# LIN_LIN_52400000h register map
Vendor: Texas Instruments
Registers are 32-bit, read-write, reset 0x0 unless marked. A register's access mark holds for its fields unless they carry their own. Offsets are as the file gives them; [hi:lo] are bit positions; <NAME> marks a mode.

## LIN (part 2 of 2)
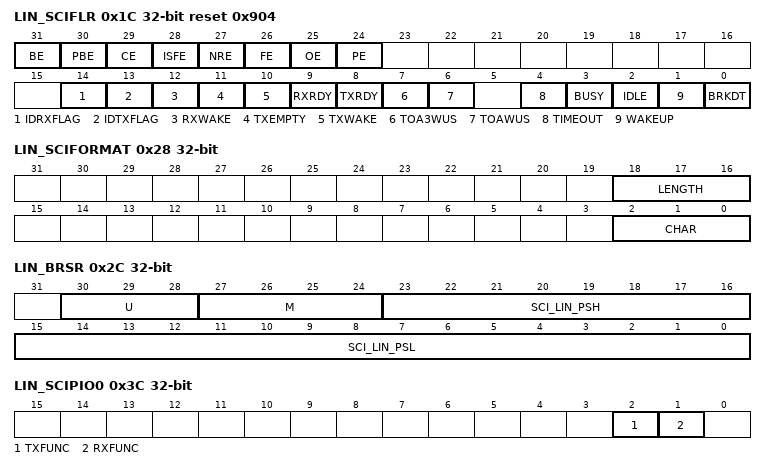
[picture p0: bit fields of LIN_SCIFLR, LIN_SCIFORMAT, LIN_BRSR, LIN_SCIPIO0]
0x1C LIN_SCIFLR access not given reset 0x904 — The SCIFLR register indicates the current status of the various interrupt sources of the LIN module.
  [31] BE — Bit Error Flag.This bit is effective in LIN mode only. This bit is set when there has been a bit error. This is detected by the bit monitor in the internal bit monitor. This bit is cleared by:- Reading the corresponding interrupt offset in the SCIINTVECT0/1 register- Setting the SWnRESET bit [SCIGCR1.7]- RESET bit [SCIGCR0.0]- System reset- Writing a 1 to this bit- Reception of a new sync break This field is writable in LIN mode only. 0 No bit error detected.1 Bit error detected. (access R/W1TC)
  [30] PBE — Physical Bus Error Flag.This bit is effective in LIN mode only. This bit is set when there has been a physical bus error. This is detected by the bit monitor in TED. This bit is cleared by:- Reading the corresponding interrupt offset in the SCIINTVECT0/1 register- Setting the SWnRESET bit [SCIGCR1.7]- RESET bit [SCIGCR0.0]- System reset- Writing a 1 to this bit- Reception of a new sync break Note: thie PBE will ony be flagged if no sync break can be generated. [because of a bus shortage to VBAT] or if no sync break delimeter can be generated [because of a bus shortage to GND]. This field is writable in LIN mode only. 0 No physiscal bus error detected.1 Physical bus error detected. (access R/W1TC)
  [29] CE — Checksum Error Flag. This bit is effective in LIN mode only. This bit is set when there is checksum error detected by a receiving node. The type of checksum to be used depends on the SCIGCR1.CTYPE bit. This bit is cleared by:- Reading the corresponding interrupt offset in the SCIINTVECT0/1 register- Setting the SWnRESET bit [SCIGCR1.7]- RESET bit [SCIGCR0.0]- System reset- Writing a 1 to this bit- Reception of a new sync break This field is writable in LIN mode only. 0 No Checksum error detected.1 Checksum error detected. (access R/W1TC)
  [28] ISFE — Inconsistent Sync Field Error Flag.This bit is effective in LIN mode only. This bit is set when there has been an inconsistent Sync Field error detected by the synchronizer during header reception. See the 'Header Reception and Adaptive Baudrate' section for more information. This bit is cleared by:- Reading the corresponding interrupt offset in the SCIINTVECT0/1 register- Setting the SWnRESET bit [SCIGCR1.7]- RESET bit [SCIGCR0.0]- System reset- Writing a 1 to this bit- Reception of a new sync break This field is writable in LIN mode only. 0 No Inconsistent Sync Field error detected.1 Inconsistent Sync Field error detected. (access R/W1TC)
  [27] NRE — No-Response Error Flag.This bit is effective in LIN mode only. This bit is set when there is no response to a master's header completed within TFRAME_MAX. This timeout period is applied for message frames of unknown length [identifiers 0 to 61]. This error is detected by the synchronizer of the module. This bit is cleared by:- Reading the corresponding interrupt offset in the SCIINTVECT0/1 register- Setting the SWnRESET bit [SCIGCR1.7]- RESET bit [SCIGCR0.0]- System reset- Writing a 1 to this bit- Reception of a new sync break This field is writable in LIN mode only. 0 No No-Response error detected.1 No-Response error detected. (access R/W1TC)
  [26] FE — Framing error flag.This bit is effective in LIN or SCI-compatible mode. This bit is set when an expected stop bit is not found. In SCI compatible mode, only the first stop bit is checked. The missing stop bit indicates that synchronization with the start bit has been lost and that the character is incorrectly framed. Detection of a framing error causes the SCI to generate an error interrupt if the RXERR INT ENA bit is set. This bit is cleared by:- Reading the corresponding interrupt offset in the SCIINTVECT0/1 register- Setting the SWnRESET bit [SCIGCR1.7]- RESET bit [SCIGCR0.0]- System reset- Writing a 1 to this bit- Reception of a new character [SCI-compatible mode], or frame [LIN mode]In multibuffer mode the frame is defined in the SCIFORMAT register. 0 No framing error detected.1 Framing error detected. (access R/W1TC)
  [25] OE — Overrun error flag.This bit is effective in LIN or SCI-compatible mode. This bit is set when the transfer of data from SCIRXSHF to SCIRD overwrites unread data already in SCIRD or the RDy buffers. Detection of an overrun error causes the LIN to generate an error interrupt if the SET OE INT bit is one. This bit is cleared by:- Reading the corresponding interrupt offset in the SCIINTVECT0/1 register- Setting the SWnRESET bit [SCIGCR1.7]- RESET bit [SCIGCR0.0]- System reset- Writing a 1 to this bit 0 No overrun error detected.1 Overrun error detected. (access R/W1TC)
  [24] PE — Parity error flag.This bit is effective in LIN or SCI-compatible mode. This bit is set when a parity error is detected in the received data. In SCI address-bit mode, the parity is calculated on the data and address bit fields of the received frame. In idle-line mode, only the data is used to calculate parity. An error is generated when a character is received with a mismatch between the number of 1s and its parity bit. For more information on parity checking, see the 'SCI Global Control Register [SCIGCR1]' description. If the parity function is disabled [that is, SCIGCR1.2 = 0], the PE flag is disabled and read as 0. Detection of a parity error causes the LIN to generate an error interrupt if the SET PE INT bit = 1. This bit is cleared by:- Reading the corresponding interrupt offset in the SCIINTVECT0/1 register- Setting the SWnRESET bit [SCIGCR1.7]- RESET bit [SCIGCR0.0]- System reset- Reception of a new charcter [SCI-compatible mode] or frame [LIN mode]- Writing a 1 to this bit 0 No parity error or parity disabled.1 Parity error detected. (access R/W1TC)
  [14] IDRXFLAG — Identifier On Receive Flag.This bit is effective in LIN mode only. This flag is set once an identifier is received with an RX match and no ID-parity error. See the 'Message Filtering and Validation' section for more details. When this flag is set it indicates that a new valid identifier has been received on an RX match. This bit is cleared by:- Reading the corresponding interrupt offset in the SCIINTVECT0/1 register- Setting the SWnRESET bit [SCIGCR1.7]- RESET bit [SCIGCR0.0]- System reset- Reading the LINID register- Writing a 1 to this bit This field is writable in LIN mode only. 0 No valid ID received.1 Valid ID RX received in LINID[23:16] on RX match. (access R/W1TC)
  [13] IDTXFLAG — Identifier On Transmit Flag.This bit is effective in LIN mode only. This flag is set once an identifier is received with a TX match and no ID-parity error. See the 'Message Filtering and Validation' section for more details. When this flag is set it indicates that a new valid identifier has been received on a TX match. This bit is cleared by: - Reading the corresponding interrupt offset in the SCIINTVECT0/1 register- RESET bit [SCIGCR0.0]- Setting SWnRESET- System reset- Reading the LINID register- Writing a 1 to this bit This field is writable in LIN mode only. 0 No valid ID received.1 Valid ID received in LINID[23:16] on TX match. (access R/W1TC)
  [12] RXWAKE ro — Receiver wakeup detect flag.This bit is effective in SCI-compatible mode only. The SCI sets this bit to indicate that the data currently in SCIRD is an address. This bit is cleared by:- RESET bit- Setting the SWnRESET bit [SCIGCR1.7]- System reset- Receipt of a data frame This bit is writable in SCI mode only. 0 The data in SCIRD is not an address.1 The data in SCIRD is an address.See [1] Section 3.4.4, Sleep Mode for Multiprocessor Communication, on page 16 for more information on using the RXWAKE bit with sleep mode.
  [11] TXEMPTY ro — Transmitter Empty flag.The value of this flag indicates the contents of the transmitter's buffer register[s] [SCITD/TDy] and shift register [SCITXSHF]. In multibuffer mode, this flag indicates the value of the TDx registers and shift register [SCITXSHF]. In non multibuffer mode, this flag indicates the value of LINTD0 [byte] and shift register [SCITXSHF]. This bit is set by: - RESET bit [SCIGCR0.0]- Setting the SWnRESET bit [SCIGCR1.7]- System reset. Note: This bit does not cause an interrupt request. 0 Compatible mode or LIN with no multibuffer:Transmitter buffer or shift register (or both) are loaded with data.In LIN mode using multibuffer mode:Multibuffer or shift register (or all) are loaded with data.1 Compatible mode or LIN with no multibuffer:Transmitter buffer and shift registers are both empty.In LIN mode using multibuffer mode:Multibuffer and shift registers are all empty.
  [10] TXWAKE rw — SCI transmitter wakeup method select.This bit is effective in SCI-compatible mode only. The TXWAKE bit controls whether the data in SCITD should be sent as an address or data frame using multiprocessor communication format. This bit is set to 1 or 0 by software before a byte is written to SCITD and is cleared by the SCI when data is transferred from SCITD to SCITXSHF or by a system reset. TXWAKE is not cleared by the SWnRESET bit [SCIGCR1.7]. 0 Address-bit mode: Frame to be transmitted will be data (address bit = 0).Idle- line mode: Frame to be transmitted will be data.1 Address-bit mode:Frame to be transmitted will be an address (address bit=1).Idle-line mode:Following frame to be transmitted will be an address (writing a 1 to this bit followed by writing dummy data to the SCITD will result in a idle period of 11 bit periods before the next frame is transmitted).
  [9] RXRDY — Receiver ready flag. In SCI compatibility mode, the receiver sets this bit to indicate that the SCIRD contains new data and is ready to be read by the CPU. In LIN mode, RXRDY is set once a valid frame is received in multibuffer mode, a valid frame being a message frame received with no errors. In non multibuffer mode RXRDY is set for each received byte and will be set for the last byte of the frame if there are no errors. The SCI/LIN generates a receive interrupt when RXRDY flag bit is setif the interrupt-enable bit is set [SCISETINT.9]. RXRDY is cleared by:- RESET bit [SCIGCR0.0]- Setting the SWnRESET- System reset- Writing a 1 to this bit- Reading SCIRD in while in SCI compatibility mode- Reading last data byte RDy of the response in LIN mode Note: The RXRDY flag cannot be cleared by Reading the corresponding interrupt offset in the SCIINTVECT0/1 register. 0 No new data in SCIRD/RDy.1 New data ready to be read from SCIRD. (access R/W1TC)
  [8] TXRDY ro — Transmitter buffer register ready flag.When set, this bit indicates that the transmit buffer[s] register [SCITD in compatibility mode and LINTD0, LINTD1 in MBUF mode] is/are ready to get another character from a CPU write. In SCI compatibility mode, Writing data to SCITD automatically clears this bit. In LIN mode, this bit is cleared once byte 0 [TD0] is written to LINTD0. This bit is set after the data of the TX buffer are shifted into the SCITXSHF register. This event can trigger a transmit DMA event if the DMA enable bit is set. This bit is set to 1 by:- RESET bit [SCIGCR0.0]- Setting the SWnRESET [SCIGCR1.7]- System reset Note: The TXRDY flag cannot be cleared by Reading the corresponding interrupt offset in the SCIINTVECT0/1 register. Note: The transmit interrupt request can be eliminated until the next series of data is written into the transmit buffers LINTD0 and LINTD1, by disaLINg the corresponding interrupt via the SCICLEARINT register or by disaLINg the transmitter via the TXENA bit [SCIGCR1.25=0]. 0 Compatible mode: SCITD is full.LIN mode: The multibuffers are full.1 Compatible mode: SCITD is ready to receive the next character.LIN mode: The multibuffers are ready to receive the next character(s).
  [7] TOA3WUS — Timeout After 3 Wakeup Signals flag.This bit is effective in LIN mode only. This flag is set if there is no Sync Break received after 3 wakeup signals and a period of 1.5 seconds have passed. Such expiration time is used before issuing another round of wakeup signals. This bit is cleared by:- Reading the corresponding interrupt offset in the SCIINTVECT0/1 register- Setting the SWnRESET bit [SCIGCR1.7]- RESET bit [SCIGCR0.0]- System reset- Writing a 1 to this bit This field is writable in LIN mode only. 0 No timeout after 3 wakeup signals.1 Timeout after 3 wakeup signals and 1.5s time. (access R/W1TC)
  [6] TOAWUS — Timeout After Wakeup Signal flag.This bit is effective in LIN mode only. This bit is set if there is no Sync Break received after a wakeup signal has been sent. A minimum of 150 ms expiration time is used before issuing another wakeup signal. This bit is cleared by:- Reading the corresponding interrupt offset in the SCIINTVECT0/1 register- Setting the SWnRESET bit [SCIGCR1.7]- RESET bit [SCIGCR0.0]- System reset- Writing a 1 to this bit This field is writable in LIN mode only. 0 No timeout after one wakeup signal (150 ms).1 Timeout after one wakeup signal. (access R/W1TC)
  [4] TIMEOUT — LIN Bus IDLE timeout flag.This bit is effective in LIN mode only. This bit is set if there is no LIN bus activity for at least 4 seconds. LIN bus activity being a transition from recessive to dominant. This bit is cleared by:- Reading the corresponding interrupt offset in the SCIINTVECT0/1 register- Setting the SWnRESET bit [SCIGCR1.7]- RESET bit [SCIGCR0.0]- System reset- Writing a 1 to this bit This field is writable in LIN mode only. 0 No bus idle detected.1 LIN bus idle detected. (access R/W1TC)
  [3] BUSY ro — Bus BUSY flag.This bit is effective in LIN mode and SCI-compatible mode. This bit indicates whether the receiver is in the process of receiving a frame. As soon as the receiver detects the beginning of a start bit, the BUSY bit is set to 1. When the reception of a frame is complete, the BUSY bit is cleared. If SET WAKEUP INT is set and power down is requested while this bit is set, the SCI/LIN automatically prevents low-power mode from being entered and generates wakeup interrupt. The BUSY bit is controlled directly by the SCI receiver but can be cleared by:- Setting the SWnRESET bit [SCIGCR1.7]- RESET bit [SCIGCR0.0]- System reset. 0 Receiver is not currently receiving a frame.1 Receiver is currently receiving a frame.
  [2] IDLE ro — SCI receiver in idle state.This bit is effective in SCI-compatible mode only. While this bit is set, the SCI looks for an idle period to resynchronize itself with the bit stream. The receiver does not receive any data while the bit is set. The bus must be idle for 11 bit periods to clear this bit. The SCI enters this state:- After a system reset- Setting the SWnRESET bit [SCIGCR1.7]- After coming out of power down This bit is writable in SCI mode only. 0 Idle period detected, the SCI is ready to receive.1 Idle period not detected, the SCI will not receive any data.
  [1] WAKEUP — Wake-up flag.This bit is effective in LIN mode only. This bit is set by the SCI/LIN when receiver or transmitter activity has taken the module out of power-down mode. An interrupt is generated if the SET WAKEUP INT bit [SCISETINT.1] is set. This bit is cleared by:- Reading the corresponding interrupt offset in the SCIINTVECT0/1 register.- Setting the SWnRESET bit [SCIGCR1.7]- RESET bit [SCIGCR0.0]- System reset- Writing a 1 to this bit. This field is writable in LIN mode only. 0 Do not wake up from power-down mode.1 Wake up from power-down mode. (access R/W1TC)
  [0] BRKDT — SCI break-detect flag.This bit is effective in SCI-compatible mode only. This bit is set when the SCI detects a break condition on the LINRX pin. A break condition occurs when the LINRX pin remains continuously low for at least 10 bits after a missing first stop bit, that is, after a framing error. Detection of a break condition causes the SCI to generate an error interrupt if the BRKDT INT ENA bit is set. The BRKDT bit is cleared by the following:- Reading the corresponding interrupt offset in the SCIINTVECT0/1 register.- Setting the SWnRESET bit [SCIGCR1.7]- RESET bit [SCIGCR0.0]- System reset- By Writing a 1 to this bit. This bit is writable in SCI mode only. 0 No break condition detected.1 Break condition detected. (access R/W1TC)
0x20 LIN_SCIINTVECT0 ro — The SCIINTVECT0 register indicates the offset for the INT0 interrupt line.
  [4:0] INTVECT0 — Interrupt vector offset for INT0.This register indicates the offset for interrupt line INT0. A read to this register updates its value to the next highest priority pending interrupt in SCIFLR and clears the flag corresponding to the offset that was read. Note: The flags for the receive [SCIFLR.9] and the transmit [SCIFLR.8] interrupts cannot be cleared by Reading the corresponding offset vector in this register [see detailed description in SCIFLR register].
0x24 LIN_SCIINTVECT1 ro — The SCIINTVECT1 register indicates the offset for the INT1 interrupt line.
  [4:0] INTVECT1 — Interrupt vector offset for INT1.This register indicates the offset for interrupt line INT1. A read to this register updates its value to the next highest priority pending interrupt in SCIFLR and clears the flag corresponding to the offset that was read. Note: The flags for the receive [SCIFLR.9] and the transmit [SCIFLR.8] interrupts cannot be cleared by Reading the corresponding offset vector in this register [see detailed description in SCIFLR register].
0x28 LIN_SCIFORMAT — The SCIFORMAT register is used to set up the character and frame lengths.
  [18:16] LENGTH — Frame length control bits.In LIN mode, these bits indicate the number of bytes in the response field from 1 to 8 bytes. In buffered SCI mode, these bits indicate the number of characters. When these bits are used to indicate LIN response length [SCIGCR1[0] = 1], then when there is an ID RX match, this value should be updated with the expected length of the response. In buffered SCI mode, these bits indicate the number of characters with SCIFORMAT[2:0] bits per character. i.e. these bits indicate the transmitter/receiver format for the number of characters: 1 to 8. There can be up to eight characters with eight bits each. 0 The response field has 1 bytes/characters.1 The response field has 2 bytes/characters.2 The response field has 3 bytes/characters.3 The response field has 4 bytes/characters.4 The response field has 5 bytes/characters.5 The response field has 6 bytes/characters.6 The response field has 7 bytes/characters.7 The response field has 8 bytes/characters.
  [2:0] CHAR — Character length control bits.These bits are effective in SCI compatible mode only. These bits set the SCI character length from 1 to 8 bits. Note: In compatibility mode or buffered SCI mode, when data of fewer than eight bits in length is received, it is left justified in SCIRD/RDy and padded with trailing zeros. Data read from the SCIRD should be shifted by software to make the received data right justified. Note: Data written to the SCITD should be right justified but does not need to be padded with leading zeros. These bits are witable in SCI mode only. 0 The character is 1 bits long.1 The character is 2 bits long.2 The character is 3 bits long.3 The character is 4 bits long.4 The character is 5 bits long.5 The character is 6 bits long.6 The character is 7 bits long.7 The character is 8 bits long.
0x2C LIN_BRSR — The BRSR register is used to configure the baud rate of the LIN module.
  [30:28] U — Superfractional Divider Selection. [U]These bits are an additional fractional part for the baudrate specification. These bits allow a super fine tuning of the fractional baudrate with 7 more intermediate values for each of the M fractional divider values. See the Superfractional Divider section for more details.
  [27:24] M — SCI/LIN 4-bit Fractional Divider Selection. [M]These bits are effective in LIN or SCI asynchronous mode. These bits are used to select a baud rate for the SCI/LIN module, and they are a fractional part for the baud rate specification. The M divider allows fine-tuning of the baud rate over the P prescaler with 15 additional intermediate values for each of the P integer values.
  [23:16] SCI_LIN_PSH — PRESCALER P [High Bits].SCI/LIN 24-bit Integer Prescaler Selection.These bits are used to select a baudrate for the SCI/LIN module. These bits are effective in LIN mode and SCI compatible mode. The SCI/LIN has an internally generated serial clock determined by the LIN module input clock and the prescalers P and M in this register. The SCI/LIN uses the 24-bit integer prescaler P value to select 1 of over 16,700,000 available baud rates. The additional 4-bit fractional prescaler M refines the baudate selection.
  [15:0] SCI_LIN_PSL — PRESCALER P [Low Bits].SCI/LIN 24-bit Integer Prescaler Selection.These bits are used to select a baudrate for the SCI/LIN module. These bits are effective in LIN mode and SCI compatible mode. The SCI/LIN has an internally generated serial clock determined by the LIN module input clock and the prescalers P and M in this register. The SCI/LIN uses the 24-bit integer prescaler P value to select 1 of over 16,700,000 available baud rates. The additional 4-bit fractional prescaler M refines the baudate selection.
0x30 LIN_SCIED ro — The SCIED register is a duplicate copy of SCIRD register that has no effect on the RXRDY flag for use with an emulator.
  [7:0] ED — Receiver Emulation Data.This bit is effective in SCI-compatible mode only. Reading SCIED[7-0] does not clear the RXRDY flag. This register should be used only by an emulator that must continually read the data buffer without affecting the RXRDY flag.
0x34 LIN_SCIRD ro — The SCIRD register is where received data is stored and can be read from.
  [7:0] RD — Received Data.This bit is effective in SCI-compatible mode only. When a frame has been completely received, the data in the frame is transferred from the receiver shift register SCIRXSHF to this register. As this transfer occurs, the RXRDY flag is set and a receive interrupt is generated if RX INT ENA [SCISETINT0.9] is set. When the data is read from SCIRD, the RXRDY flag is automatically cleared. When the SCI receives data that is fewer than eight bits in length, it loads the data into this register in a left justified format padded with trailing zeros. Therefore, your software should perform a logical shift on the data by the correct number of positions to make it right justified.
0x38 LIN_SCITD — The SCITD register is where data to be transmitted is written to by application software.
  [7:0] TD — Transmit dataThis bit is effective in SCI-compatible mode only. Data to be transmitted is written to this register. The transfer of data from this register to the transmit shift register SCITXSHF sets the TXRDY flag [SCIFLR.23], which indicates that SCITD is ready to be loaded with another byte of data. Note: If TX INT ENA [SCISETINT.8] is set, this data transfer also causes an interrupt. Note: Data written to the SCIRD register that is fewer than eight bits long must be right justified, but it does not need to be padded with leading zeros.
0x3C LIN_SCIPIO0 — The SCIPIO0 register is used to enable the LINTX and LINRX pins.
  [2] TXFUNC — Transmit pin function.This bit is effective in LIN or SCI mode. This bit defines the function of LINTX pin. 0 LINTX pin is disabled.1 LINTX pin is enabled.
  [1] RXFUNC — Receive pin function.This bit is effective in LIN or SCI mode. This bit defines the function of the LINRX pin. 0 LINRX pin is disabled.1 LINRX pin is enabled.
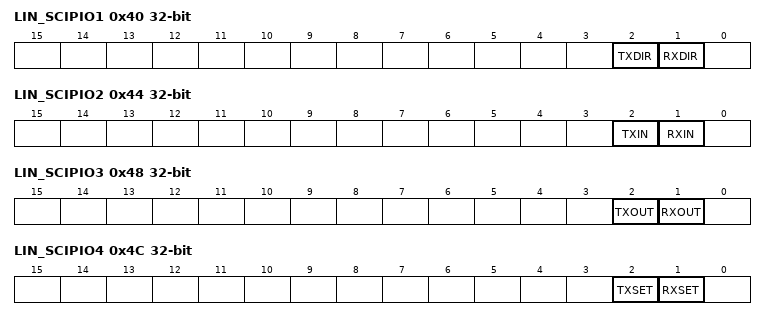
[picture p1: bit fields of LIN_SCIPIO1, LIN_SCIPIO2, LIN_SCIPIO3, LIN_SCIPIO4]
0x40 LIN_SCIPIO1 — Pin control Register 1
  [2] TXDIR — Transmit pin direction.This bit is effective in LIN or SCI mode. This bit determines the data direction on the LINTX pin if it is configured with general-purpose I/O functionality [TX FUNC = 0].0:general purpose input pin.1:general-purpose output pin
  [1] RXDIR — Receive pin direction.This bit is effective in LIN or SCI mode. This bit determines the data direction on the LINRX pin if it is configured with general-purpose I/O functionality [RX FUNC = 0].0:general purpose input pin.1:general-purpose output pin
0x44 LIN_SCIPIO2 ro — The SCIPIO2 register indicates the current status of the LINTX and LINRX pins.
  [2] TXIN — Transmit data in.This bit is effective in LIN or SCI-compatible mode. This bit contains the current value on the LINTX pin.
  [1] RXIN — Receive data in.This bit is effective in LIN or SCI-compatible mode. This bit contains the current value on the LINRX pin.
0x48 LIN_SCIPIO3 — Pin control Register 3
  [2] TXOUT — Transmit pin out.This bit is effective in LIN or SCI mode. This pin specifies the logic to be output on pin LINTX.
  [1] RXOUT — Receive pin out.This bit is effective in LIN or SCI mode. This pin specifies the logic to be output on pin LINRX.
0x4C LIN_SCIPIO4 access not given — Pin control Register 4
  [2] TXSET — Transmit pin set.This bit is effective in LIN or SCI mode. This bit sets the logic to be output on pin LINTX. (access R/W1TS)
  [1] RXSET — Receive pin set.This bit is effective in LIN or SCI mode. This bit sets the logic to be output on pin LINRX. (access R/W1TS)
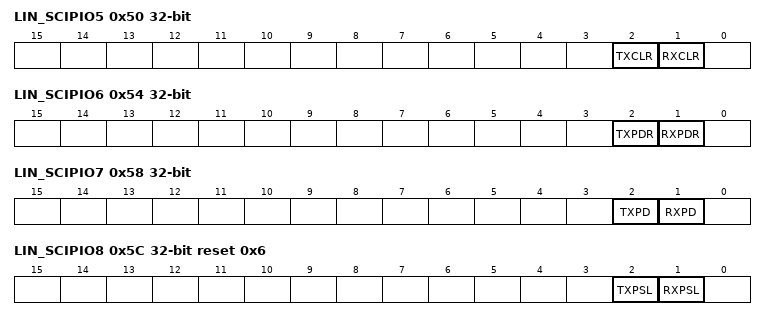
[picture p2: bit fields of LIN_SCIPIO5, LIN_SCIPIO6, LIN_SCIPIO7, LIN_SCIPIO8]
0x50 LIN_SCIPIO5 access not given — Pin control Register 5
  [2] TXCLR — Transmit pin clear.This bit is effective in LIN or SCI mode. This bit clears the logic to be output on pin LINTX. (access R/W1TC)
  [1] RXCLR — Receive pin clear.This bit is effective in LIN or SCI mode. This bit clears the logic to be output on pin LINRX. (access R/W1TC)
0x54 LIN_SCIPIO6 — Pin control Register 6
  [2] TXPDR — Transmit pin open drain enable.This bit is effective in LIN or SCI mode. This bit enables open-drain capability in the output pin LINTX.
  [1] RXPDR — Receive pin open drain enable.This bit is effective in LIN or SCI mode. This bit enables open-drain capability in the output pin LINRX.
0x58 LIN_SCIPIO7 — Pin control Register 7
  [2] TXPD — Transmit pin pull control disable.This bit is effective in LIN or SCI mode. This bit disables pull control capability on the input pin LINTX.
  [1] RXPD — Receive pin pull control disable.This bit is effective in LIN or SCI mode. This bit disables pull control capability on the input pin LINRX.
0x5C LIN_SCIPIO8 reset 0x6 — Pin control Register 8
  [2] TXPSL — TX pin pull select.This bit is effective in LIN or SCI mode. This bit selects pull type in the input pin LINTX.
  [1] RXPSL — RX pin pull select.This bit is effective in LIN or SCI mode. This bit selects pull type in the input pin LINRX.
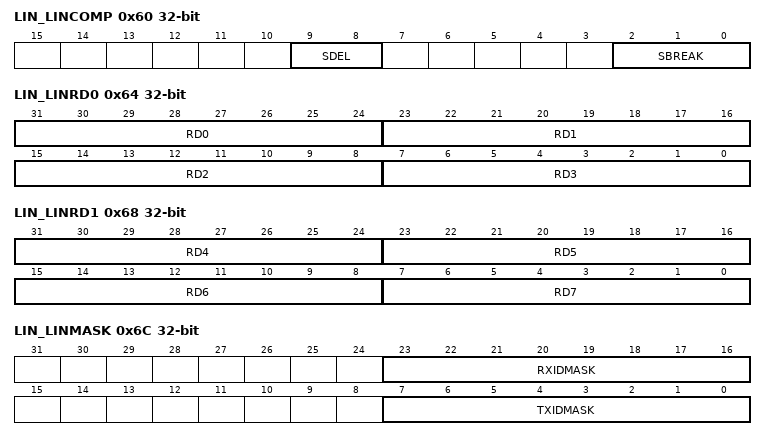
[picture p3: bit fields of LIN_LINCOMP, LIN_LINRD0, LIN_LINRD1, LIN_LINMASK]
0x60 LIN_LINCOMP — The LINCOMPARE register is used to configure the sync delimeter and sync break extension.
  [9:8] SDEL — 2-bit Sync Delimiter compare.These bits are effective in LIN mode only. These bits are used to configure the number of Tbit for the sync delimiter in the sync field.The time delay calculation for the synchronization delimiter is:TSDEL = [SDEL + 1]Tbit These bits are writable in LIN mode only. 0 The sync delimiter has 1 Tbit.1 The sync delimiter has 2 Tbit.2 The sync delimiter has 3 Tbit.3 The sync delimiter has 4 Tbit.
  [2:0] SBREAK — 3-bit Sync Break extend.LIN mode only. These bits are used to configure the number of Tbits for the sync break to extend the minimum 13 Tbit in the Sync Field to a maximum of 20 Tbit.The time delay calculation for the sync break is:TSYNBRK = 13Tbit + SBREAK x Tbit These bits are writable in LIN mode only. 0 The sync break has no additional Tbit.1 The sync break has 1 additional Tbit.2 The sync break has 2 additional Tbit.3 The sync break has 3 additional Tbit.4 The sync break has 4 additional Tbit.5 The sync break has 5 additional Tbit.6 The sync break has 6 additional Tbit.7 The sync break has 7 additional Tbit.
0x64 LIN_LINRD0 ro — The LINRD0 register contains the lower 4 bytes of the received LIN frame data.
  [31:24] RD0 — 8-bit Receive Buffer 0Each response data-byte that is received in the SCIRXSHFT register is transferred to the corresponding RDy register according to the number of bytes received.A read of this byte clears the RXDY byte.Note: RD<x-1> is equivalent to Data byte <x> of the LIN frame.
  [23:16] RD1 — 8-bit Receive Buffer 1.Each response data-byte that is received in the SCIRXSHFT register is transferred to the corresponding RDy register according to the number of bytes received.
  [15:8] RD2 — 8-bit Receive Buffer 2.Each response data-byte that is received in the SCIRXSHFT register is transferred to the corresponding RDy register according to the number of bytes received.
  [7:0] RD3 — 8-bit Receive Buffer 3.Each response data-byte that is received in the SCIRXSHFT register is transferred to the corresponding RDy register according to the number of bytes received.
0x68 LIN_LINRD1 ro — The LINRD1 regsiter contains the upper 4 bytes of the received LIN frame data.
  [31:24] RD4 — 8-bit Receive Buffer 4 Each response data-byte that is received in the SCIRXSHFT register is transferred to the corresponding RDy register according to the number of bytes received.
  [23:16] RD5 — 8-bit Receive Buffer 5.Each response data-byte that is received in the SCIRXSHFT register is transferred to the corresponding RDy register according to the number of bytes received.
  [15:8] RD6 — 8-bit Receive Buffer 6.Each response data-byte that is received in the SCIRXSHFT register is transferred to the corresponding RDy register according to the number of bytes received.
  [7:0] RD7 — 8-bit Receive Buffer 7.Each response data-byte that is received in the SCIRXSHFT register is transferred to the corresponding RDy register according to the number of bytes received.
0x6C LIN_LINMASK — The LINMASK register is used to configure the masks used for filtering incoming ID messages for receive and transmit frames.
  [23:16] RXIDMASK — Receive ID mask.This field is effective in LIN mode only.This 8-bit mask is used for filtering an incoming ID message and compare it to the ID-byte. A compare match of the received ID witht the RX ID mask will set the ID RX flag and trigger and ID interrupt if enabled. A 0 bit in the mask indicates that bit is compared to the ID-byte. A 1 bit in the mask indicates that that bit is filtered and therefore not used in the compare. When HGENCTRL is set to 1, this field must be set to 0xFF.
  [7:0] TXIDMASK — Transmit ID mask.This field is effective in LIN mode only. This 8-bit mask is used for filtering an incoming ID message and compare it to the ID-byte. A compare match of the received ID with the TX ID Mask will set the ID TX flag and trigger an ID interrupt if enabled. A 0 bit in the mask indicates that bit is compared to the ID-byte. A 1 bit in the mask indicates that bit is filtered and therefore not used for the compare. When HGENCTRL is set to 1, this field must be set to 0xFF.
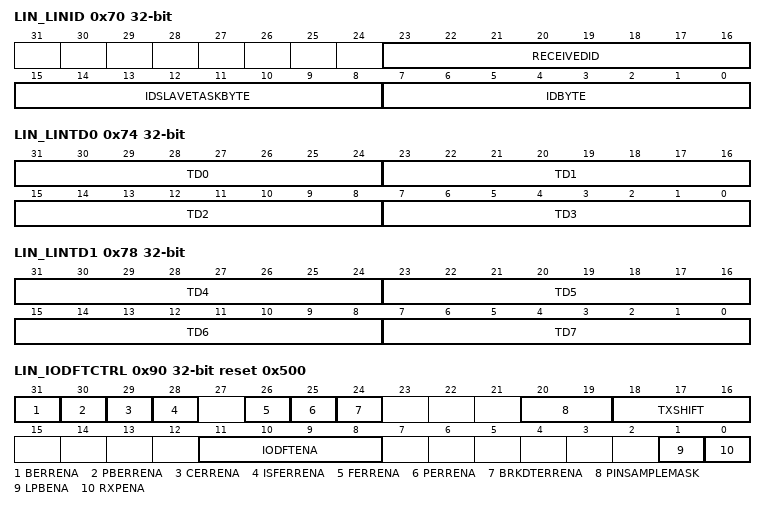
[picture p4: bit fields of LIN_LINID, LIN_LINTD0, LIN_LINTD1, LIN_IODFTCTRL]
0x70 LIN_LINID access per field — The LINID register contains the identification fields for LIN communication.NOTE: For software compatibility with future LIN modules, the HGEN CTRL bit must be set to 1, the RX ID MASK field must be set to FFh, and the TX ID MASK field must be set to FFh.
  [23:16] RECEIVEDID ro — Received ID.This bit is effective in LIN mode only. This byte contains the current message identifier. During header reception the received ID is copied from the SCIRXSHF register to this byte if there is no ID-parity error and there has been an RX/TX match.Note: If a framing error [FE] is detected during ID reception, the received ID will also not be copied to the LINID register.
  [15:8] IDSLAVETASKBYTE rw — ID Target Task byte.This field is effective in LIN mode only. This byte contains the identifier to which the received ID of an incoming header will be compared in order to decide whether a RX response, a TX response, or no action needs to be done by the LIN node. These bits are writable in LIN mode only.
  [7:0] IDBYTE rw — ID byte.This field is effective in LIN mode only. This byte is the LIN mode message ID. On a master node, a write to this register by the CPU initiates a header transmission. For a target task, this byte is used for message filtering when HGENCTRL [SCIGCR1.12] is '0'. These bits are writable in LIN mode only.
0x74 LIN_LINTD0 — The LINTD0 register contains the lower 4 bytes of the data to be transmitted.NOTE: TD<x-1> is equivalent to Data byte <x> of the LIN frame.
  [31:24] TD0 — 8-bit Transmit Buffer 0.Byte 0 to be transmitted is written into this register and then copied to SCITXSHF for transmission. Once byte 0 is written in TDO buffer, transmission will be initiated.
  [23:16] TD1 — 8-bit Transmit Buffer 3.Byte 1 to be transmitted is written into this register and then copied to SCITXSHF for transmission.
  [15:8] TD2 — 8-bit Transmit Buffer 2.Byte 2 to be transmitted is written into this register and then copied to SCITXSHF for transmission.
  [7:0] TD3 — 8-bit Transmit Buffer 3.Byte 3 to be transmitted is written into this register and then copied to SCITXSHF for transmission.
0x78 LIN_LINTD1 — The LINTD1 register contains the upper 4 bytes of the data to be transmitted.NOTE: TD<x-1> is equivalent to Data byte <x> of the LIN frame.
  [31:24] TD4 — 8-bit Transmit Buffer 4.Byte4 to be transmitted is written into this register and then copied to SCITXSHF for transmission.
  [23:16] TD5 — 8-bit Transmit Buffer 5.Byte 5 to be transmitted is written into this register and then copied to SCITXSHF for transmission.
  [15:8] TD6 — 8-bit Transmit Buffer 6.Byte 6 to be transmitted is written into this register and then copied to SCITXSHF for transmission.
  [7:0] TD7 — 8-bit Transmit Buffer 7.Byte 7 to be transmitted is written into this register and then copied to SCITXSHF for transmission.
0x7C LIN_MBRSR reset 0xDAC — The MBRSR register is used to configure the expected maximum baud rate of the LIN network.
  [12:0] MBR — Maximum Baud Rate Prescaler.This field is effective in LIN mode only. This 13-bit prescaler is used during the synchronization phase [see the 'Header Reception and Adaptive Baudrate' section] of a target module if the ADAPT bit is set. In this way, a SCI/LIN target using an automatic or select bit rate modes detects any LIN bus legal rate automatically. The MBR value should be programmed to allow a maximum baud rate that is not more than 10% above the expected operating baud rate in the LIN network. Otherwise a s 0x00 data byte could mistakenly be detected as sync break.The default value is for a 70MHz LINCLK [0xDAC].This MBR prescaler is used by the wake-up and idle time counters for a constant expiration time relative to a 20kHz rate.
0x80 LIN_RESERVED_1_j access not given reset not defined
0x90 LIN_IODFTCTRL reset 0x500 — The IODFTCTRL register is used to emulate various error and test conditions.
  [31] BERRENA — Bit Errror Enable bit.This bit is effective in LIN mode only. This bit is used to create a Bit error. When this bit is set, the bit received is ORed with 1 and passed to the Bit monitor circuitry.
  [30] PBERRENA — Physical Bus Error Enable bit.This bit is effective in LIN mode only. This bit is used to create a Physical Bus Error. When this bit is set, the bit received during Sync Break field transmission is ORed with 1 and passed to the Bit monitor circuitry
  [29] CERRENA — Checksum Error Enable bit.This bit is effective in LIN mode only. This bit is used to create a checksum error. When this bit is set, the polarity of the CTYPE [checksum type] in the receive checksum calculator is changed so that a checksum error is generated.
  [28] ISFERRENA — Inconsistent Sync Field Error Enable bit.This bit is effective in LIN mode only. This bit is used to create an ISF error. When this bit is set, the bit widths in the sync field are varied so that the ISF check fails and the error flag is set.
  [26] FERRENA — This bit is used to create a Frame Error.This bit is effective in SCI-compatible mode only. When this bit is set, the stop bit received is ANDed with '0' and passed to the stop bit check circuitry.
  [25] PERRENA — Compatible Mode onlyThis bit is effective in SCI-compatible mode only. This bit is used to create a Parity Error. When this bit is set, in compatible mode, the parity bit received is toggled so that a parity error occurs.
  [24] BRKDTERRENA — Compatible Mode onlyThis bit is effective in SCI-compatible mode only. This bit is used to create BRKDT error [SCI mode only]. When this bit is set, the stop bit of the frame is ANDed with '0' and passed to the RSM so that a frame error occurs. Then the RX Pin is forced to continuous low for 10 Tbits so that a BRKDT error occurs.
  [20:19] PINSAMPLEMASK — Pin sample mask.These bits define the sample number at which the TX Pin value that is being transmitted will be inverted to verify the receive pin samples correctly with the majority detection circuitry.Note: During IODFT mode testing for the pin sample mask, the prescalar P must be programmed to be greater than 2. 0 No Mask1 Invert the TX Pin value at TBIT_CENTER2 Invert the TX Pin value at TBIT_CENTER + SCLK3 Invert the TX Pin value at TBIT_CENTER + 2 SCLK
  [18:16] TXSHIFT — Transmit shift.These bits define the delay by which the value on LINTX is delayed so that the value on LINRX is asynchronous. [Not applicable to Start Bit] 0 No Delay1 Delay by 1 SCLK2 Delay by 2 SCLK3 Delay by 3 SCLK4 Delay by 4 SCLK5 Delay by 5 SCLK6 Delay by 6 SCLK7 Delay by 7 SCLK
  [11:8] IODFTENA — IO DFT Enable KeyThis field is used to enable the IODFT mode of the SCI/LIN module for testing. 0 IODFT is disabled1 IODFT is disabled2 IODFT is disabled3 IODFT is disabled4 IODFT is disabled5 IODFT is disabled6 IODFT is disabled7 IODFT is disabled8 IODFT is disabled9 IODFT is disabled10 IODFT is enabled11 IODFT is disabled12 IODFT is disabled13 IODFT is disabled14 IODFT is disabled15 IODFT is disabled
  [1] LPBENA — Module loopback enable.In analog loopback mode the complete communication path through the I/Os can be tested, whereas in digital loopback mode the I/O buffers are excluded from this path. 0 Digital loopback is enabled.1 Analog loopback is enabled in module I/O DFT mode (when IODFTENA = 1010)
  [0] RXPENA — Module Analog loopback through receive pin enable.This bit defines whether the I/O buffers for the transmit or the receive pin are included in the communication path in analog loopback mode only. 0 Analog loopback through the transmit pin is enabled.1 Analog loopback through the receive pin is enabled.
0x94 LIN_RESERVED_2_j access not given reset not defined
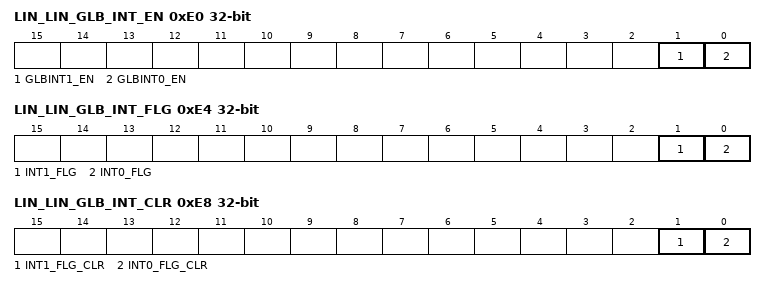
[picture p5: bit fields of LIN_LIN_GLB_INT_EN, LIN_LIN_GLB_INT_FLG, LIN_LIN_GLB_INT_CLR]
0xE0 LIN_LIN_GLB_INT_EN — The LIN_GLB_INT_EN register is used to enable the INT0 and INT1 interrupt lines to propagate to the PIE block.
  [1] GLBINT1_EN — Global Interrupt Enable for LIN INT1.This bit determines whether the INT1 interrupt line generates an interrupt to the PIE or not 0 LIN INT1 line does not generate an interrupt to the PIE.1 LIN INT1 line generates an interrupt to the PIE if an enabled interrupt condition occurs.
  [0] GLBINT0_EN — Global Interrupt Enable for LIN INT0.This bit determines whether the INT0 interrupt line generates an interrupt to the PIE or not. 0 LIN INT0 line does not generate an interrupt to the PIE.1 LIN INT0 line generates an interrupt to the PIE if an enabled interrupt condition occurs.
0xE4 LIN_LIN_GLB_INT_FLG ro — The LIN_GLB_INT_FLG register contains the current status of the INT0 and INT1 flags.
  [1] INT1_FLG — Global Interrupt Flag for LIN INT1.This bit indicates if an interrupt was generated to the PIE due to an enabled interrupt on the INT1 interrupt line. Refer to the LIN Interrupt Status Register for the condition that generated the interrupt.This bit can be cleared by Writing a 1 to the corresponding bit in the LIN_GLB_INT_CLR register. 0 No interrupt is active on the INT1 line.1 An interrupt was generated due to an enabled interrupt on the INT1 interrupt line.
  [0] INT0_FLG — Global Interrupt Flag for LIN INT0.This bit indicates if an interrupt was generated to the PIE due to an enabled interrupt on the INT0 interrupt line. Refer to the LIN Interrupt Status Register for the condition that generated the interrupt.This bit can be cleared by Writing a 1 to the corresponding bit in the LIN_GLB_INT_CLR register. 0 No interrupt is active on the INT0 line.1 An interrupt was generated due to an enabled interrupt on the INT0 interrupt line.
0xE8 LIN_LIN_GLB_INT_CLR access not given — The LIN_GLB_INT_CLR register is used to clear the interrupt flags in LIN_GLB_INT_FLG register.
  [1] INT1_FLG_CLR — Global Interrupt flag clear for LIN INT1.This bit is used to clear the corresponding bit in the LIN_GLB_INT_FLG register. Write 1 to clear the INT1_FLG bit. Writing 0 has no effect. (access R/W1TC)
  [0] INT0_FLG_CLR — Global Interrupt flag clear for LIN INT0.This bit is used to clear the corresponding bit in the LIN_GLB_INT_FLG register. Write 1 to clear the INT0_FLG bit. Writing 0 has no effect. (access R/W1TC)
